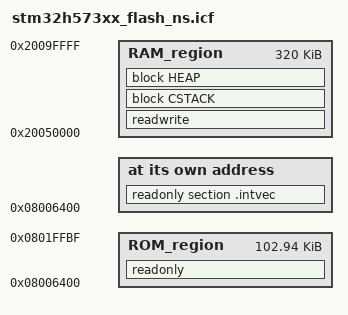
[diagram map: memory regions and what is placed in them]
/*###ICF### Section handled by ICF editor, don't touch! ****/
/*-Editor annotation file-*/
/* IcfEditorFile="$TOOLKIT_DIR$\config\ide\IcfEditor\cortex_v1_0.xml" */
/*-Specials-*/
define exported symbol S_CODE_OFFSET = 0x00000000; /* This define is updated automatically from ROT_BOOT project */
define exported symbol S_CODE_SIZE = 0x00006000; /* This define is updated automatically from ROT_BOOT project */
define exported symbol NS_CODE_OFFSET = S_CODE_OFFSET + S_CODE_SIZE; /* Non secure code Offset */
define exported symbol NS_CODE_SIZE = 0x1A000; /* This define is updated automatically from ROT_BOOT project */
define exported symbol IMAGE_HEADER_SIZE = 0x400; /* mcuboot headre size */
define symbol TRAILER_MAX_SIZE = 0x40; /* max size trailer */

define exported symbol __ICFEDIT_intvec_start__ = 0x08000000 + NS_CODE_OFFSET + IMAGE_HEADER_SIZE;
/*-Memory Regions-*/
define exported symbol __ICFEDIT_region_ROM_start__     = 0x08000000 + NS_CODE_OFFSET + IMAGE_HEADER_SIZE;
define symbol __ICFEDIT_region_ROM_end__       = 0x08000000 + NS_CODE_OFFSET + NS_CODE_SIZE - TRAILER_MAX_SIZE - 1;
define symbol __ICFEDIT_region_RAM_start__ = 0x20050000;
define symbol __ICFEDIT_region_RAM_end__   = 0x2009FFFF;

/*-Sizes-*/
define symbol __ICFEDIT_size_cstack__ = 0x400;
define symbol __ICFEDIT_size_heap__   = 0x200;
/**** End of ICF editor section. ###ICF###*/


define memory mem with size = 4G;
define region ROM_region      = mem:[from __ICFEDIT_region_ROM_start__   to __ICFEDIT_region_ROM_end__];
define region RAM_region      = mem:[from __ICFEDIT_region_RAM_start__   to __ICFEDIT_region_RAM_end__];

define block CSTACK    with alignment = 8, size = __ICFEDIT_size_cstack__   { };
define block HEAP      with alignment = 8, size = __ICFEDIT_size_heap__     { };

initialize by copy { readwrite };
do not initialize  { section .noinit };

place at address mem:__ICFEDIT_intvec_start__ { readonly section .intvec };

place in ROM_region   { readonly };
place in RAM_region   { readwrite,
                        block CSTACK, block HEAP };
